# target register map
Vendor: Vango; Series: TARGET; File version: 1.0
CPU: CM0 r0p0, little endian, no MPU, no FPU, 2 interrupt priority bits
Registers are 32-bit, read-write, reset 0x0 unless marked. A register's access mark holds for its fields unless they carry their own. Offsets are from the block's base; [hi:lo] are bit positions.

## GPIOA — The GPIO controller is used to control the GPIOs of TARGET.
Base 0x40014010
0x00 OEN reset 0xFFFF — IOA output enable register
  [15:0] IOAOEN — Each bit control the IOA output enable signal.
0x04 IE reset 0xFFFF — IOA input enable register
  [15:0] IOAIE — Each bit control the IOA output enable signal.
0x08 DAT — IOA data register
  [15:0] IOADAT — Each bit control the IOA output data and pull low/high function.
0x0C ATT — IOA attribute register
  [15:0] IOAATT — Each bit control the IOA attribute.
0x10 IOAWKUEN — IOA wake-up enable register
  [31:0] WKUEN — Every 2 bits control the IOA' s wake up function. Bit [1:0]: IOA0 Bit [3:2]: IOA1 ... Bit [31:30]: IOA15
0x14 STS ro reset not defined — IOA input status register
  [15:0] IOASTS — Each bit represents the current IOA input data value.
0x18 IOAINTSTS — IOA interrupt status register.
  [15:0] INTSTS write-1-clears — Each bit represents the IOA' s interrupt status.
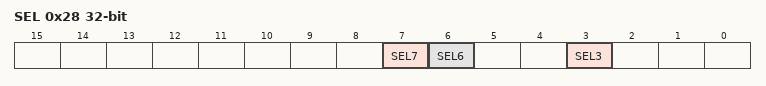
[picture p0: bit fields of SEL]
0x28 SEL — IOA special function select register.
  [7] SEL7 — IOA7 special function select register.
  [6] SEL6 — IOA6 special function select register.
  [3] SEL3 — IOA3 special function select register.
0x40 IOANODEG — IOA no-deglitch control register.
  [15:0] NODEG — Each bit control if the IOA wake-up signal will go through de-glitch circuit or not.

## GPIOB — The GPIO controller is used to control the GPIOs of TARGET.
Base 0x40000020
Same registers: GPIOC 0x40000040, GPIOD 0x40000060, GPIOE 0x40000080, GPIOF 0x400000A0
0x00 OEN reset 0xFFFF — IO output enable register
  [15:0] IOXOEN — Each bit controls the IOX output enable signal.
0x04 IE reset 0xFFFF — IO input enable register
  [15:0] IOXIE — Each bit controls the IOX’s input enable signal.
0x08 DAT — IO data register
  [15:0] IOXDAT — Each bit controls the IOX output data and pull low/high function.
0x0C ATT — IO attribute register
  [15:0] IOXATT — Each bit control the IOX attribute.
0x10 STS ro — IO input status register
  [15:0] IOXSTS — Each bit represents the current IOX input data value.

## GPIOAF — The GPIO controller is used to control the GPIOs of TARGET.
Base 0x400000C0
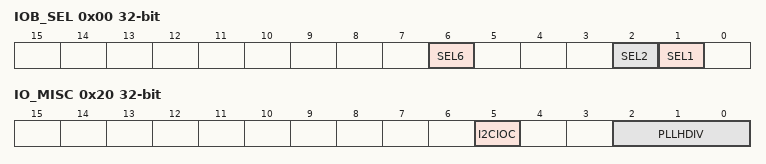
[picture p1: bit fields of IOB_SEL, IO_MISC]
0x00 IOB_SEL — IOB special function select register.
  [6] SEL6 — IOB6 special function select register.
  [2] SEL2 — IOB2 special function select register.
  [1] SEL1 — IOB1 special function select register.
0x0C IOE_SEL (reset mask 0x8) — IOE special function select register.
  [7] SEL7 — IOE7 special function select register.
0x20 IO_MISC — IO misc. control register.
  [5] I2CIOC — This register is used to control the I2C function is at IOB or IOC.
    0=IOB13_IOB14; 1=IOC4_IOC5
  [2:0] PLLHDIV — When IOB1 is selected to special function 3, this register is used to control the divide ratio of PLLH' s output.
    0=Div1; 1=Div2; 2=Div4; 3=Div8; 4=Div16

## I2C — I2C-Inter Integrated Circuit
Base 0x40010800
0x00 DATA — I2C data register.
  [7:0] DATA — The I2C_DATA register.
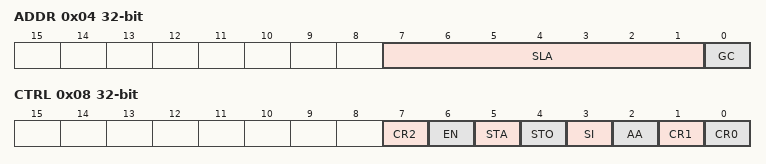
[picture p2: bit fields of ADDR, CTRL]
0x04 ADDR — I2C address register.
  [7:1] SLA — Own I2C slave address (7 bit) .
  [0] GC — General Call Address Acknowledge.
0x08 CTRL — I2C control/status register.
  [7] CR2 — Clock rate bit 2.
  [6] EN — I2C enable bit.
  [5] STA — START Flag.
  [4] STO — STOP Flag.
  [3] SI write-0-clears — Serial Interrupt Flag.
  [2] AA — Assert Acknowledge Flag.
  [1] CR1 — Clock rate bit 1.
  [0] CR0 — Clock rate bit 0.
0x0C STS ro reset 0xF8 — I2C status register.
  [7:3] STS — I2C Status Code.
0x18 CTRL2 — I2C interrupt enable register.
  [0] INTEN — Interrupt enable control of I2C controller.

## ISO78160 — The ISO7816 controller is an enhance UART protocol which is able to do half-duplex communication on the 2 wires bus.
Base 0x40012000
Same registers: ISO78161 0x40012040
0x04 BAUDDIVL — ISO7816 baud-rate low byte register
  [7:0] BAUDDIVL — Low byte of baud-rate divider.
0x08 BAUDDIVH — ISO7816 baud-rate high byte register
  [7:0] BAUDDIVH — High byte of baud_rate divider.
0x0C DATA — ISO7816 data register.
  [7:0] DATA — Read: Receive data, when receive data is not read by programmer and another data has been received, the OVIF flag will be set. Write: Transmit data, a write to this port will trigger a transmit event on the ISO7816 bus.
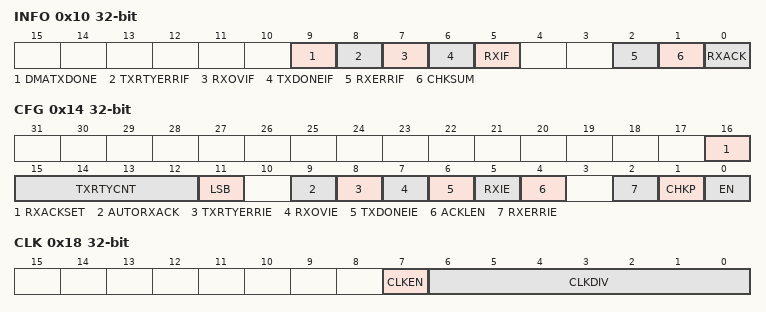
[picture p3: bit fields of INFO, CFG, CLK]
0x10 INFO — ISO7816 information register.
  [9] DMATXDONE write-1-clears — Transmit finish flag.
  [8] TXRTYERRIF write-1-clears — Transmit Retry counter reach flag.
  [7] RXOVIF write-1-clears — Receive overflow flag.
  [6] TXDONEIF write-1-clears — Transmit interrupt flag.
  [5] RXIF write-1-clears — Receive interrupt flag.
  [2] RXERRIF write-1-clears — When received data have check sum error, this bit will be set to 1.
  [1] CHKSUM — The transmitted or received data check sum bit. This bit can be read/write by CPU, by the original message will be lost.
  [0] RXACK — The received ACK at the end of transmit. This bit can be read/write by CPU, by the original message will be lost.
0x14 CFG — ISO7816 control register.
  [16] RXACKSET — RXACK length.
  [15:12] TXRTYCNT — Transmit retry number control register.
  [11] LSB — MSB/LSB transmit order control register.
  [9] AUTORXACK — Automatic response ACK as 0 when receive an error data to let transmitter re-send the data.
  [8] TXRTYERRIE — Transmit retry error interrupt enable register
  [7] RXOVIE — Receive overrun interrupt enable register.
  [6] TXDONEIE — Transmit interrupt enable register.
  [5] RXIE — Receive interrupt enable register.
  [4] ACKLEN — ACK low period when receive an error data.
  [2] RXERRIE — Received data error interrupt enable register.
  [1] CHKP — Parity mode control register.
  [0] EN — ISO7816 enable register.
0x18 CLK — ISO7816 clock divider control register.
  [7] CLKEN — ISO7816 clock output enable.
  [6:0] CLKDIV — The ISO7816 clock divider ratio.
